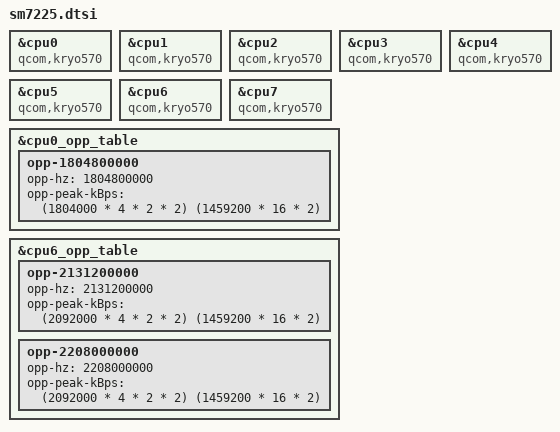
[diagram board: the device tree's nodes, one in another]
// SPDX-License-Identifier: BSD-3-Clause
/*
 * Copyright (c) 2021, Luca Weiss <luca@z3ntu.xyz>
 */

#include "sm6350.dtsi"

/* SM7225 uses Kryo 570 instead of Kryo 560 */
&cpu0 { compatible = "qcom,kryo570"; };
&cpu1 { compatible = "qcom,kryo570"; };
&cpu2 { compatible = "qcom,kryo570"; };
&cpu3 { compatible = "qcom,kryo570"; };
&cpu4 { compatible = "qcom,kryo570"; };
&cpu5 { compatible = "qcom,kryo570"; };
&cpu6 { compatible = "qcom,kryo570"; };
&cpu7 { compatible = "qcom,kryo570"; };

&cpu0_opp_table {
	opp-1804800000 {
		opp-hz = /bits/ 64 <1804800000>;
		opp-peak-kBps = <(1804000 * 4 * 2 * 2) (1459200 * 16 * 2)>;
	};
};

&cpu6_opp_table {
	opp-2131200000 {
		opp-hz = /bits/ 64 <2131200000>;
		opp-peak-kBps = <(2092000 * 4 * 2 * 2) (1459200 * 16 * 2)>;
	};

	opp-2208000000 {
		opp-hz = /bits/ 64 <2208000000>;
		opp-peak-kBps = <(2092000 * 4 * 2 * 2) (1459200 * 16 * 2)>;
	};
};
